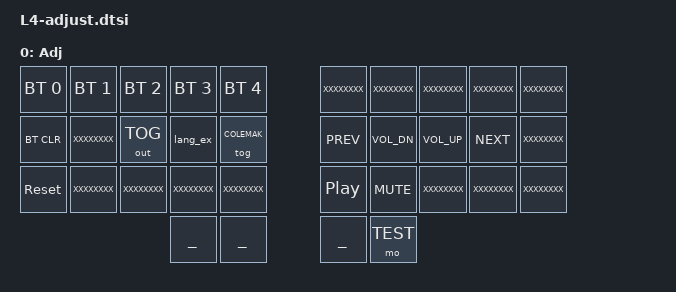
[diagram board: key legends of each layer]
/**
 *
 */

/ {
  keymap {
    compatible = "zmk,keymap";

	adjust_layer {
		label = "Adj";
   		bindings = <
//	╭───────────────┬───────────────┬───────────────┬───────────────┬───────────────╮   ╭───────────────┬───────────────┬───────────────┬───────────────┬───────────────╮
    &bt BT_SEL 0    &bt BT_SEL 1    &bt BT_SEL 2    &bt BT_SEL 3    &bt BT_SEL 4		XXXXXXXX        XXXXXXXX     	XXXXXXXX		XXXXXXXX		XXXXXXXX
//	├───────────────┼───────────────┼───────────────┼───────────────┼───────────────┤   ├───────────────├───────────────┼───────────────┼───────────────┼───────────────┤
	  &bt BT_CLR		XXXXXXXX		&out OUT_TOG	&lang_ex		&tog COLEMAK		&kp C_PREV		&kp C_VOL_DN	&kp C_VOL_UP	&kp C_NEXT		XXXXXXXX
//	├───────────────┼───────────────┼───────────────┼───────────────┼───────────────┤   ├───────────────├───────────────┼───────────────┼───────────────┼───────────────┤
	  &sys_reset		XXXXXXXX		XXXXXXXX        XXXXXXXX		XXXXXXXX			&kp C_PP		&kp C_MUTE		XXXXXXXX		XXXXXXXX        XXXXXXXX
//	╰───────────────┴───────────────┼───────────────┼───────────────┼───────────────┤   ├───────────────├───────────────┼───────────────┼───────────────┴───────────────╯
	       											________		________			________		&mo TEST
//                                                  ╰───────────────┴───────────────╯   ╰───────────────┴───────────────╯
			>;
		};
	};
};
